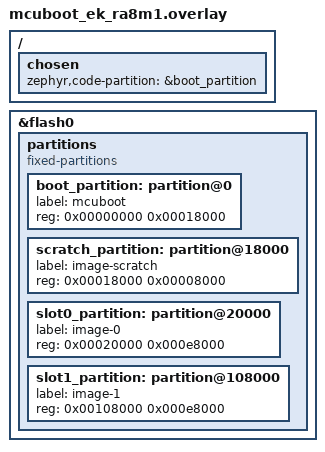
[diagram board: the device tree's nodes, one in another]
/ {
	chosen {
		zephyr,code-partition = &boot_partition;
	};
};

&flash0 {
	partitions {
		compatible = "fixed-partitions";
		#address-cells = <1>;
		#size-cells = <1>;

		boot_partition: partition@0 {
			label = "mcuboot";
			reg = <0x00000000 0x00018000>;
		};

		scratch_partition: partition@18000 {
			label = "image-scratch";
			reg = <0x00018000 0x00008000>;
		};

		slot0_partition: partition@20000 {
			label = "image-0";
			reg = <0x00020000 0x000e8000>;
		};

		slot1_partition: partition@108000 {
			label = "image-1";
			reg = <0x00108000 0x000e8000>;
		};

	};
};
